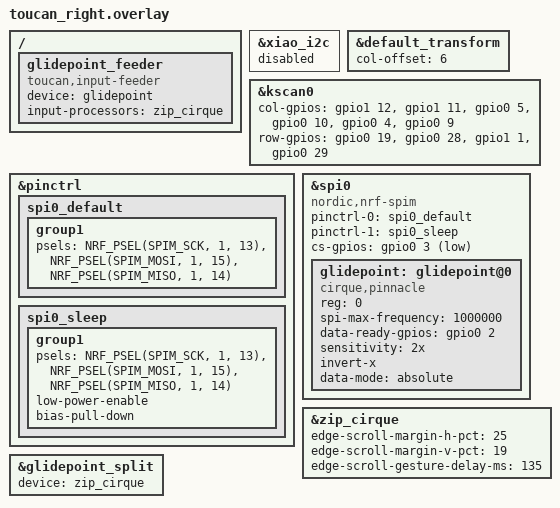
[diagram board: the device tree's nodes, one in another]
#include "toucan.dtsi"
#include <input/processors.dtsi>
#include <dt-bindings/zmk/input_transform.h>
#include <input/processors/cirque.dtsi>

&xiao_i2c {
    status = "disabled";
};

&default_transform {
    col-offset = <6>;
};

&kscan0 {
    col-gpios
    = <&gpio1 12 GPIO_ACTIVE_HIGH>
    , <&gpio1 11 GPIO_ACTIVE_HIGH>
    , <&gpio0 5 GPIO_ACTIVE_HIGH>
    , <&gpio0 10 GPIO_ACTIVE_HIGH>
    , <&gpio0 4 GPIO_ACTIVE_HIGH>
    , <&gpio0 9 GPIO_ACTIVE_HIGH>
    ;

    row-gpios
    = <&gpio0 19 (GPIO_ACTIVE_HIGH | GPIO_PULL_DOWN)>
    , <&gpio0 28 (GPIO_ACTIVE_HIGH | GPIO_PULL_DOWN)>
    , <&gpio1 1 (GPIO_ACTIVE_HIGH | GPIO_PULL_DOWN)>
    , <&gpio0 29 (GPIO_ACTIVE_HIGH | GPIO_PULL_DOWN)>
    ;
};

&pinctrl {
    spi0_default: spi0_default {
        group1 {
            psels = <NRF_PSEL(SPIM_SCK, 1, 13)>,
                <NRF_PSEL(SPIM_MOSI, 1, 15)>,
                <NRF_PSEL(SPIM_MISO, 1, 14)>;
        };
    };

     spi0_sleep: spi0_sleep {
        group1 {
            psels = <NRF_PSEL(SPIM_SCK, 1, 13)>,
                    <NRF_PSEL(SPIM_MOSI, 1, 15)>,
                    <NRF_PSEL(SPIM_MISO, 1, 14)>;
            low-power-enable;
            bias-pull-down; // minimize power leakage during sleep
        };
    };

};

&spi0 {
   compatible = "nordic,nrf-spim";
   status = "okay";
   pinctrl-0 = <&spi0_default>;
   pinctrl-1 = <&spi0_sleep>;
   pinctrl-names = "default", "sleep";
   cs-gpios = <&gpio0 3 (GPIO_ACTIVE_LOW | GPIO_PULL_UP)>;  // pull-up to ensure CS is !asserted when asleep
   glidepoint:  glidepoint@0 {
        compatible = "cirque,pinnacle";
        reg = <0>;
        spi-max-frequency = <1000000>;
        status = "okay";
        data-ready-gpios = <&gpio0 2 (GPIO_ACTIVE_HIGH)>;
        sensitivity = "2x";
        invert-x;

        // Report absolute X/Y/Z; gestures (tap, edge scroll, ...) are handled by &zip_cirque below
        data-mode = "absolute";

        // Optional: hardware sleep after 5 seconds with no touches. It wakes up on touch, but there is a
        // ~300ms delay.
        //sleep-mode-enable;
    };
};

/*
 * Gesture processing runs here on the peripheral (timing sensitive, and only the
 * resulting relative motion / wheel / buttons are sent to the central):
 *   pad (absolute) --glidepoint_feeder--> &zip_cirque --glidepoint_split--> central
 *
 * The feeder (toucan,input-feeder, src/input_feeder.c in this repo) is used instead of a
 * second zmk,input-split: two split inputs on one peripheral make the central's GATT
 * discovery read a bogus reg and drop every trackpad event.
 *
 *   - centre: cursor (flick to glide), tap = left click, tap + hold = drag
 *   - rim:    tap = right click, rest a moment then circle = scroll wheel
 */
&zip_cirque {
    edge-scroll-margin-h-pct = <25>;      // larger = wider rim / smaller cursor area
    edge-scroll-margin-v-pct = <19>;
    edge-scroll-gesture-delay-ms = <135>; // rest on the rim this long before scrolling starts
    // inertial-disable;                  // uncomment to turn off the glide after a flick
};

/ {
    glidepoint_feeder: glidepoint_feeder {
        compatible = "toucan,input-feeder";
        device = <&glidepoint>;
        input-processors = <&zip_cirque>;
    };
};

&glidepoint_split {
    device = <&zip_cirque>;
};
